# ATxmega256A3BU device description
Architecture: AVR8_XMEGA; Family: AVR XMEGA
Registers are 8-bit, access not given, no defined reset value unless marked. A register's access mark holds for its fields unless they carry their own. Offsets are from the block's base; [hi:lo] are bit positions.

## TWI_MASTER — Two-Wire Interface
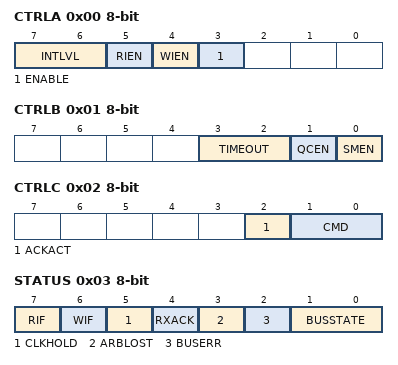
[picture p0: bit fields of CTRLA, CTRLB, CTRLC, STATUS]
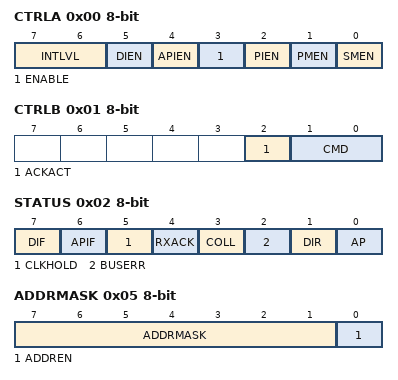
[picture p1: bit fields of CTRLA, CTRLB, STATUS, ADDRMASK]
0x00 CTRLA — Control Register A
  [7:6] INTLVL — Interrupt Level
    0=OFF (Interrupt Disabled); 1=LO (Low Level); 2=MED (Medium Level); 3=HI (High Level)
  [5] RIEN — Read Interrupt Enable
  [4] WIEN — Write Interrupt Enable
  [3] ENABLE — Enable TWI Master
0x01 CTRLB — Control Register B
  [3:2] TIMEOUT — Inactive Bus Timeout
    0=DISABLED (Bus Timeout Disabled); 1=50US (50 Microseconds); 2=100US (100 Microseconds); 3=200US (200 Microseconds)
  [1] QCEN — Quick Command Enable
  [0] SMEN — Smart Mode Enable
0x02 CTRLC — Control Register C
  [2] ACKACT — Acknowledge Action
  [1:0] CMD — Command
    0=NOACT (No Action); 1=REPSTART (Issue Repeated Start Condition); 2=RECVTRANS (Receive or Transmit Data); 3=STOP (Issue Stop Condition)
0x03 STATUS
  [7] RIF — Read Interrupt Flag
  [6] WIF — Write Interrupt Flag
  [5] CLKHOLD — Clock Hold
  [4] RXACK — Received Acknowledge
  [3] ARBLOST — Arbitration Lost
  [2] BUSERR — Bus Error
  [1:0] BUSSTATE
    0=UNKNOWN (Unknown Bus State); 1=IDLE (Bus is Idle); 2=OWNER (This Module Controls The Bus); 3=BUSY (The Bus is Busy)
0x04 BAUD — Baud Rate Control Register
0x05 ADDR — Address Register
0x06 DATA

## TWI_SLAVE — Two-Wire Interface
0x00 CTRLA — Control Register A
  [7:6] INTLVL — Interrupt Level
    0=OFF (Interrupt Disabled); 1=LO (Low Level); 2=MED (Medium Level); 3=HI (High Level)
  [5] DIEN — Data Interrupt Enable
  [4] APIEN — Address/Stop Interrupt Enable
  [3] ENABLE — Enable TWI Slave
  [2] PIEN — Stop Interrupt Enable
  [1] PMEN — Promiscuous Mode Enable
  [0] SMEN — Smart Mode Enable
0x01 CTRLB — Control Register B
  [2] ACKACT — Acknowledge Action
  [1:0] CMD — Command
    0=NOACT (No Action); 2=COMPTRANS (Used To Complete a Transaction); 3=RESPONSE (Used in Response to Address/Data Interrupt)
0x02 STATUS
  [7] DIF — Data Interrupt Flag
  [6] APIF — Address/Stop Interrupt Flag
  [5] CLKHOLD — Clock Hold
  [4] RXACK — Received Acknowledge
  [3] COLL — Collision
  [2] BUSERR — Bus Error
  [1] DIR — Read/Write Direction
  [0] AP — Slave Address or Stop
0x03 ADDR — Address Register
0x04 DATA
0x05 ADDRMASK — Address Mask Register
  [7:1] ADDRMASK — Address Mask
  [0] ADDREN — Address Enable

## TWI — Two-Wire Interface
Instances: TWIC 0x480, TWIE 0x4A0
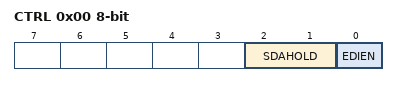
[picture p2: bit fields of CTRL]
0x00 CTRL — TWI Common Control Register
  [2:1] SDAHOLD — SDA Hold Time Enable
    0=OFF (SDA Hold Time off); 1=50NS (SDA Hold Time 50 ns); 2=300NS (SDA Hold Time 300 ns); 3=400NS (SDA Hold Time 400 ns)
  [0] EDIEN — External Driver Interface Enable

## USB_EP — USB Endpoint
0x00 STATUS — Endpoint Status
  [7] STALLF — Endpoint Stall Flag
  [7] CRC — CRC Error Flag
  [6] UNF — Underflow Enpoint FLag
  [6] OVF — Overflow Enpoint Flag for Output Endpoints
  [5] TRNCOMPL0 — Transaction Complete 0 Flag
  [4] TRNCOMPL1 — Transaction Complete 1 Flag
  [4] SETUP — SETUP Transaction Complete Flag
  [3] BANK — Bank Select
  [2] BUSNACK1 — Data Buffer 1 Not Acknowledge
  [1] BUSNACK0 — Data Buffer 0 Not Acknowledge
  [0] TOGGLE — Data Toggle
0x01 CTRL — Endpoint Control
  [7:6] TYPE — Endpoint Type
    0=DISABLE (Endpoint Disabled); 1=CONTROL; 2=BULK (Bulk/Interrupt); 3=ISOCHRONOUS
  [5] MULTIPKT — Multi Packet Transfer Enable
  [4] PINGPONG — Ping-Pong Enable
  [3] INTDSBL — Interrupt Disable
  [2] STALL — Data Stall
  [2:0] BUFSIZE — Data Buffer Size
    0=8 bytes buffer size; 1=16 bytes buffer size; 2=32 bytes buffer size; 3=64 bytes buffer size; 4=128 bytes buffer size; 5=256 bytes buffer size; 6=512 bytes buffer size; 7=1023 bytes buffer size
0x02 CNT 16-bit — USB Endpoint Counter
  [15] ZLP — Zero Length Packet
0x04 DATAPTR 16-bit — Data Pointer
0x06 AUXDATA 16-bit — Auxiliary Data
